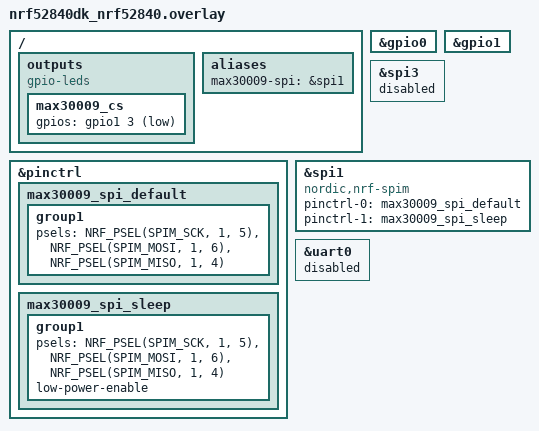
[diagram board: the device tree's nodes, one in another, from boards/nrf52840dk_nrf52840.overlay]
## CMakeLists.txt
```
# SPDX-License-Identifier: Apache-2.0

cmake_minimum_required(VERSION 3.20.0)

find_package(Zephyr REQUIRED HINTS $ENV{ZEPHYR_BASE})
project(app)

target_sources(app PRIVATE 
    src/main.c
    src/max30009/max30009.c
    src/max30009/spi_functions.c
)
```

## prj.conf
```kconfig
CONFIG_LOG=y
CONFIG_LOG_PRINTK=y
CONFIG_GPIO=y

CONFIG_SPI=y
```

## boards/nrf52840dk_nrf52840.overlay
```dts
&pinctrl {
	max30009_spi_default: max30009_spi_default {
		group1 {
			psels = <NRF_PSEL(SPIM_SCK, 1, 5)>,
				<NRF_PSEL(SPIM_MOSI, 1, 6)>,
				<NRF_PSEL(SPIM_MISO, 1, 4)>;
		};
	};

	max30009_spi_sleep: max30009_spi_sleep {
		group1 {
			psels = <NRF_PSEL(SPIM_SCK, 1, 5)>,
				<NRF_PSEL(SPIM_MOSI, 1, 6)>,
				<NRF_PSEL(SPIM_MISO, 1, 4)>;
			low-power-enable;
		};
	};

};

/{
    outputs{
        compatible = "gpio-leds";
        max30009_cs: max30009_cs{
            gpios = < &gpio1 3 (GPIO_PUSH_PULL | GPIO_ACTIVE_LOW) >;
        };
    };

    aliases {
        max30009-spi = &spi1;
    };
};

&gpio0 {
	status = "okay";
};

&gpio1{
	status = "okay";
};

&spi3 {
	status = "disabled";
};


&spi1 {
	compatible = "nordic,nrf-spim";
    status = "okay";
    pinctrl-0 = < &max30009_spi_default >;
    pinctrl-1 = < &max30009_spi_sleep >;
};

&uart0 {
    status = "disabled";
};
```

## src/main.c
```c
/*
 * Copyright (c) 2012-2014 Wind River Systems, Inc.
 *
 * SPDX-License-Identifier: Apache-2.0
 */

#include <zephyr/kernel.h>
#include <zephyr/logging/log.h>

LOG_MODULE_REGISTER(MAIN, LOG_LEVEL_DBG);

#include "max30009/max30009.h"

int main(void)
{
	const uint8_t fifo_afull_threshold = 5;
	uint8_t status_1 = 0;
	uint8_t bioz_fifo_raw[3];
	bool pll_locked = false;
	max30009_conf_t default_conf = F_BIOZ_500KHZ_CONF;

	if(max30009_init(&default_conf)){
		// return 1;
	}

	if(max30009_set_fifo_afull_threshold(fifo_afull_threshold)){
		// return 1;
	}

	if(max30009_bioz_enable_mux()){
		// return 1;
	}

	if(max30009_conf_assign_electrodes(MAX30009_BIP_ASSIGN_EL2A, MAX30009_BIN_ASSIGN_EL3A, 
										MAX30009_DRVP_ASSIGN_EL1, MAX30009_DRVN_ASSIGN_EL4)){
		// return 1;
	}

	if(max30009_set_stimulus_mode(MAX30009_STIMULUS_MODE_SINEWAVE_VOLTAGE)){
		// return 1;
	}

	if(max30009_enable_pll(true)){
		// return 1;
	}

	while(1){

		if(max30009_get_status_1(&status_1)){
			continue;
		}

		LOG_DBG("Status 1: 0x%02x", status_1);

		if((status_1 & (1 << FREQ_LOCK_SHIFT) || status_1 & (1 << PHASE_LOCK_SHIFT))){
			if(!pll_locked){
				LOG_DBG("PLL locked ");
			}

			pll_locked = true;
			// if(max30009_start_bioz()){
			// 	LOG_DBG("Start BioZ measurement fail");
			// 	// max30009_init(&default_conf); // Soft reset
			// 	// return 1;
			// }
		}
		else{
			if(pll_locked){
				LOG_DBG("PLL Sync lost");
			}
			pll_locked = false;
		}

		// if(pll_locked){
		// 	if(status_1 & (1 << FIFO_DATA_RDY_SHIFT) && !(status_1 & (1 << PWR_RDY_SHIFT))){
		// 		if(max30009_read_fifo(bioz_fifo_raw, sizeof(bioz_fifo_raw))){
		// 			continue;
		// 		}

		// 		LOG_DBG("Fifo Raw %02x, %02x, %02x", bioz_fifo_raw[0], bioz_fifo_raw[1], bioz_fifo_raw[2]);

		// 		int32_t fifo_data = 0;
		// 		int fifo_tag = max30009_parse_fifo_data(bioz_fifo_raw, &fifo_data);
		// 		LOG_DBG("FIFO tag %d, data %d", fifo_tag, fifo_data);
		// 	}
		// }

		k_sleep(K_MSEC(100));
	}

	return 0;
}
```
